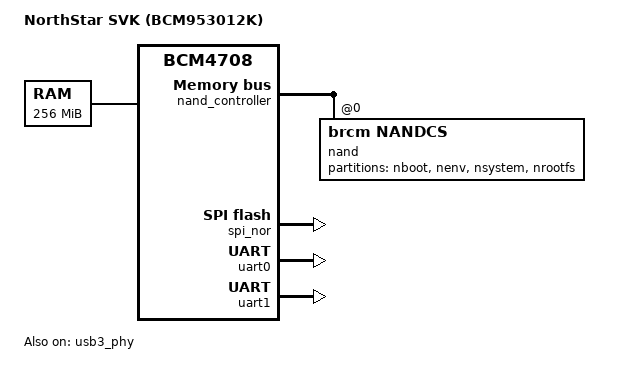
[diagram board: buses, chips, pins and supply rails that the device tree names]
/dts-v1/;
#include "bcm4708.dtsi"
/ {
	model = "NorthStar SVK (BCM953012K)";
	compatible = "brcm,bcm953012k", "brcm,bcm53012", "brcm,bcm4708";
	aliases {
		serial0 = &uart0;
		serial1 = &uart1;
	};
	memory@80000000 {
		device_type = "memory";
		reg = <0x80000000 0x10000000>;
	};
};
&nand_controller {
	nand@0 {
		compatible = "brcm,nandcs";
		reg = <0>;
		nand-on-flash-bbt;
		#address-cells = <1>;
		#size-cells = <1>;
		nand-ecc-strength = <4>;
		nand-ecc-step-size = <512>;
		partition@0 {
			label = "nboot";
			reg = <0x00000000 0x00200000>;
			read-only;
		};
		partition@200000 {
			label = "nenv";
			reg = <0x00200000 0x00400000>;
		};
		partition@600000 {
			label = "nsystem";
			reg = <0x00600000 0x00a00000>;
		};
		partition@1000000 {
			label = "nrootfs";
			reg = <0x01000000 0x07000000>;
		};
	};
};
&spi_nor {
	status = "okay";
	spi-max-frequency = <62500000>;
	m25p,default-addr-width = <3>;
	#address-cells = <1>;
	#size-cells = <1>;
	partition@0 {
		label = "boot";
		reg = <0x00000000 0x000d0000>;
	};
	partition@d000 {
		label = "env";
		reg = <0x000d0000 0x00030000>;
	};
	partition@100000 {
		label = "system";
		reg = <0x00100000 0x00600000>;
	};
	partition@700000 {
		label = "rootfs";
		reg = <0x00700000 0x00900000>;
	};
};
&uart0 {
	status = "okay";
};
&uart1 {
	status = "okay";
};
&usb3_phy {
	status = "okay";
};
